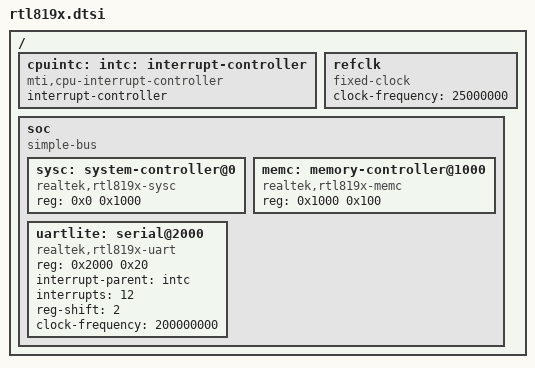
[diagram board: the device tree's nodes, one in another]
// SPDX-License-Identifier: GPL-2.0
/dts-v1/;

/ {
	#address-cells = <1>;
	#size-cells = <1>;

	cpuintc: intc: interrupt-controller {
		compatible = "mti,cpu-interrupt-controller";
		interrupt-controller;
		#interrupt-cells = <1>;
	};

	refclk: refclk {
		compatible = "fixed-clock";
		#clock-cells = <0>;
		clock-frequency = <25000000>;
	};

	soc: soc {
		compatible = "simple-bus";
		ranges = <0x0 0x18000000 0x10000>;
		#address-cells = <1>;
		#size-cells = <1>;

		sysc: system-controller@0 {
			compatible = "realtek,rtl819x-sysc";
			reg = <0x0 0x1000>;
		};

		memc: memory-controller@1000 {
			compatible = "realtek,rtl819x-memc";
			reg = <0x1000 0x100>;
		};

		uartlite: serial@2000 {
			compatible = "realtek,rtl819x-uart", "ns16550a";
			reg = <0x2000 0x20>;
			interrupt-parent = <&intc>;
			interrupts = <12>;
			reg-shift = <2>;
			clock-frequency = <200000000>;
			status = "okay";
		};
	};
};
